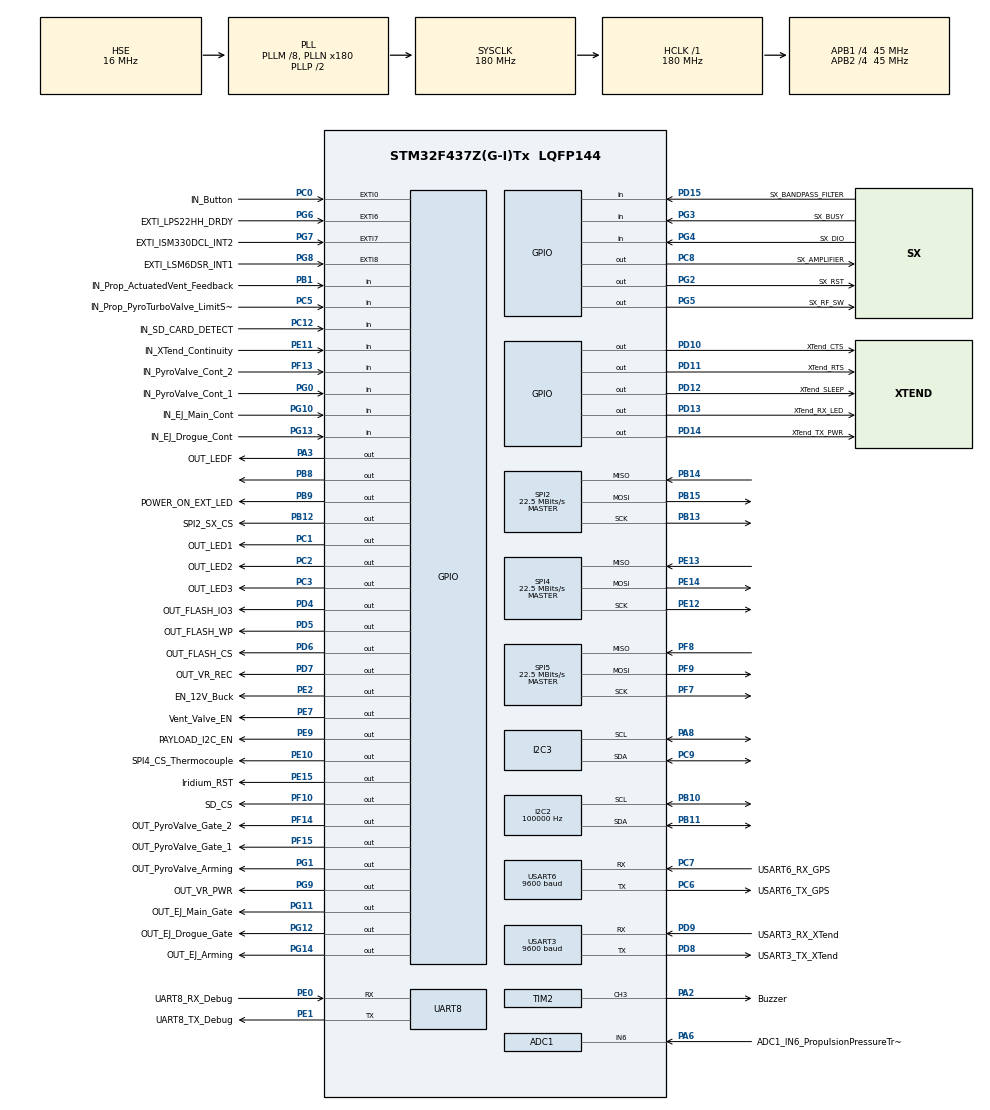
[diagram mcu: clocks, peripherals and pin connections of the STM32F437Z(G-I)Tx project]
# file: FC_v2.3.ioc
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ADC1.Channel-0\#ChannelRegularConversion=ADC_CHANNEL_6
ADC1.NbrOfConversionFlag=1
ADC1.Rank-0\#ChannelRegularConversion=1
ADC1.SamplingTime-0\#ChannelRegularConversion=ADC_SAMPLETIME_3CYCLES
ADC1.master=1
FREERTOS.INCLUDE_vTaskDelay=1
FREERTOS.Tasks01=Memory0,40,512,StartMemory0,Default,NULL,Dynamic,NULL,NULL;Ejection1,40,512,StartEjection1,Default,NULL,Dynamic,NULL,NULL;Telemetry2,48,1024,StartTelemetry2,Default,NULL,Dynamic,NULL,NULL;Sensors3,40,512,StartSensors3,Default,NULL,Dynamic,NULL,NULL;WatchDog,48,512,StartWatchDog,Default,NULL,Dynamic,NULL,NULL;Propulsion4,40,512,StartPropulsion4,Default,NULL,Dynamic,NULL,NULL
FREERTOS.configCHECK_FOR_STACK_OVERFLOW=0
FREERTOS.configMINIMAL_STACK_SIZE=512
FREERTOS.configTIMER_TASK_PRIORITY=55
FREERTOS.configTOTAL_HEAP_SIZE=24000
FREERTOS.configUSE_DAEMON_TASK_STARTUP_HOOK=1
FREERTOS.configUSE_NEWLIB_REENTRANT=1
I2C2.ClockSpeed=100000
I2C2.I2C_Mode=I2C_Standard
IWDG.Prescaler=IWDG_PRESCALER_64
IWDG.Reload=2499
Mcu.Family=STM32F4
Mcu.Name=STM32F437Z(G-I)Tx
Mcu.Package=LQFP144
NVIC.EXTI0_IRQn=true\:0\:0\:true\:false\:true\:false\:true\:true\:true
NVIC.PriorityGroup=NVIC_PRIORITYGROUP_4
NVIC.RTC_Alarm_IRQn=true\:0\:0\:true\:false\:false\:false\:true\:true\:true
NVIC.RTC_WKUP_IRQn=true\:0\:0\:true\:false\:true\:false\:true\:true\:true
NVIC.TIM6_DAC_IRQn=true\:15\:0\:true\:false\:true\:false\:false\:true\:true
NVIC.TimeBase=TIM6_DAC_IRQn
NVIC.TimeBaseIP=TIM6
PA13.Mode=Trace_Asynchronous_SW
PA13.Signal=SYS_JTMS-SWDIO
PA14.Mode=Trace_Asynchronous_SW
PA14.Signal=SYS_JTCK-SWCLK
PA2.GPIO_Label=Buzzer
PA2.Signal=S_TIM2_CH3
PA3.GPIO_Label=OUT_LEDF
PA3.Signal=GPIO_Output
PA6.GPIO_Label=ADC1_IN6_PropulsionPressureTransducer
PA6.Signal=ADCx_IN6
PA8.GPIO_Pu=GPIO_PULLUP
PA8.Mode=I2C
PA8.Signal=I2C3_SCL
PB1.GPIO_Label=IN_Prop_ActuatedVent_Feedback
PB1.Signal=GPIO_Input
PB10.GPIO_Pu=GPIO_PULLUP
PB10.Mode=I2C
PB10.Signal=I2C2_SCL
PB11.GPIO_Pu=GPIO_PULLUP
PB11.Mode=I2C
PB11.Signal=I2C2_SDA
PB12.GPIO_Label=SPI2_SX_CS
PB12.Signal=GPIO_Output
PB13.Mode=Full_Duplex_Master
PB13.Signal=SPI2_SCK
PB14.Mode=Full_Duplex_Master
PB14.Signal=SPI2_MISO
PB15.Mode=Full_Duplex_Master
PB15.Signal=SPI2_MOSI
PB3.Mode=Trace_Asynchronous_SW
PB3.Signal=SYS_JTDO-SWO
PB8.Signal=GPIO_Output
PB9.GPIO_Label=POWER_ON_EXT_LED
PB9.Signal=GPIO_Output
PC0.GPIO_Label=IN_Button
PC0.GPIO_ModeDefaultEXTI=GPIO_MODE_IT_FALLING
PC0.Signal=GPXTI0
PC1.GPIO_Label=OUT_LED1
PC1.Signal=GPIO_Output
PC12.GPIO_Label=IN_SD_CARD_DETECT
PC12.Signal=GPIO_Input
PC14/OSC32_IN.Mode=LSE-External-Oscillator
PC14/OSC32_IN.Signal=RCC_OSC32_IN
PC15/OSC32_OUT.Mode=LSE-External-Oscillator
PC15/OSC32_OUT.Signal=RCC_OSC32_OUT
PC2.GPIO_Label=OUT_LED2
PC2.Signal=GPIO_Output
PC3.GPIO_Label=OUT_LED3
PC3.Signal=GPIO_Output
PC5.GPIO_Label=IN_Prop_PyroTurboValve_LimitSwitch
PC5.Signal=GPIO_Input
PC6.GPIO_Label=USART6_TX_GPS
PC6.Mode=Asynchronous
PC6.Signal=USART6_TX
PC7.GPIO_Label=USART6_RX_GPS
PC7.Mode=Asynchronous
PC7.Signal=USART6_RX
PC8.GPIO_Label=SX_AMPLIFIER
PC8.Signal=GPIO_Output
PC9.GPIO_Pu=GPIO_PULLUP
PC9.Mode=I2C
PC9.Signal=I2C3_SDA
PD10.GPIO_Label=XTend_CTS
PD10.Signal=GPIO_Output
PD11.GPIO_Label=XTend_RTS
PD11.Signal=GPIO_Output
PD12.GPIO_Label=XTend_SLEEP
PD12.Signal=GPIO_Output
PD13.GPIO_Label=XTend_RX_LED
PD13.Signal=GPIO_Output
PD14.GPIO_Label=XTend_TX_PWR
PD14.Signal=GPIO_Output
PD15.GPIO_Label=SX_BANDPASS_FILTER
PD15.Signal=GPIO_Input
PD4.GPIO_Label=OUT_FLASH_IO3
PD4.GPIO_ModeDefaultOutputPP=GPIO_MODE_OUTPUT_PP
PD4.GPIO_PuPd=GPIO_PULLUP
PD4.PinState=GPIO_PIN_SET
PD4.Signal=GPIO_Output
PD5.GPIO_Label=OUT_FLASH_WP
PD5.GPIO_PuPd=GPIO_PULLUP
PD5.PinState=GPIO_PIN_SET
PD5.Signal=GPIO_Output
PD6.GPIO_Label=OUT_FLASH_CS
PD6.GPIO_PuPd=GPIO_PULLUP
PD6.PinState=GPIO_PIN_SET
PD6.Signal=GPIO_Output
PD7.GPIO_Label=OUT_VR_REC
PD7.Signal=GPIO_Output
PD8.GPIO_Label=USART3_TX_XTend
PD8.Mode=Asynchronous
PD8.Signal=USART3_TX
PD9.GPIO_Label=USART3_RX_XTend
PD9.Mode=Asynchronous
PD9.Signal=USART3_RX
PE0.GPIO_Label=UART8_RX_Debug
PE0.Mode=Asynchronous
PE0.Signal=UART8_RX
PE1.GPIO_Label=UART8_TX_Debug
PE1.Mode=Asynchronous
PE1.Signal=UART8_TX
PE10.GPIO_Label=SPI4_CS_Thermocouple
PE10.Signal=GPIO_Output
PE11.GPIO_Label=IN_XTend_Continuity
PE11.Signal=GPIO_Input
PE12.Mode=Full_Duplex_Master
PE12.Signal=SPI4_SCK
PE13.Mode=Full_Duplex_Master
PE13.Signal=SPI4_MISO
PE14.Mode=Full_Duplex_Master
PE14.Signal=SPI4_MOSI
PE15.GPIO_Label=Iridium_RST
PE15.Signal=GPIO_Output
PE2.GPIO_Label=EN_12V_Buck
PE2.Signal=GPIO_Output
PE7.GPIO_Label=Vent_Valve_EN
PE7.Signal=GPIO_Output
PE9.GPIO_Label=PAYLOAD_I2C_EN
PE9.Signal=GPIO_Output
PF10.GPIO_Label=SD_CS
PF10.GPIO_PuPd=GPIO_PULLUP
PF10.PinState=GPIO_PIN_SET
PF10.Signal=GPIO_Output
PF13.GPIO_Label=IN_PyroValve_Cont_2
PF13.Signal=GPIO_Input
PF14.GPIO_Label=OUT_PyroValve_Gate_2
PF14.Signal=GPIO_Output
PF15.GPIO_Label=OUT_PyroValve_Gate_1
PF15.Signal=GPIO_Output
PF7.GPIO_PuPd=GPIO_PULLUP
PF7.Mode=Full_Duplex_Master
PF7.Signal=SPI5_SCK
PF8.GPIO_PuPd=GPIO_PULLUP
PF8.Mode=Full_Duplex_Master
PF8.Signal=SPI5_MISO
PF9.GPIO_PuPd=GPIO_PULLUP
PF9.Mode=Full_Duplex_Master
PF9.Signal=SPI5_MOSI
PG0.GPIO_Label=IN_PyroValve_Cont_1
PG0.Signal=GPIO_Input
PG1.GPIO_Label=OUT_PyroValve_Arming
PG1.Signal=GPIO_Output
PG10.GPIO_Label=IN_EJ_Main_Cont
PG10.Signal=GPIO_Input
PG11.GPIO_Label=OUT_EJ_Main_Gate
PG11.Signal=GPIO_Output
PG12.GPIO_Label=OUT_EJ_Drogue_Gate
PG12.Signal=GPIO_Output
PG13.GPIO_Label=IN_EJ_Drogue_Cont
PG13.Signal=GPIO_Input
PG14.GPIO_Label=OUT_EJ_Arming
PG14.Signal=GPIO_Output
PG2.GPIO_Label=SX_RST
PG2.Signal=GPIO_Output
PG3.GPIO_Label=SX_BUSY
PG3.Signal=GPIO_Input
PG4.GPIO_Label=SX_DIO
PG4.Signal=GPIO_Input
PG5.GPIO_Label=SX_RF_SW
PG5.Signal=GPIO_Output
PG6.GPIO_Label=EXTI_LPS22HH_DRDY
PG6.Signal=GPXTI6
PG7.GPIO_Label=EXTI_ISM330DCL_INT2
PG7.Signal=GPXTI7
PG8.GPIO_Label=EXTI_LSM6DSR_INT1
PG8.Signal=GPXTI8
PG9.GPIO_Label=OUT_VR_PWR
PG9.Signal=GPIO_Output
PH0/OSC_IN.Mode=HSE-External-Oscillator
PH0/OSC_IN.Signal=RCC_OSC_IN
PH1/OSC_OUT.Mode=HSE-External-Oscillator
PH1/OSC_OUT.Signal=RCC_OSC_OUT
ProjectManager.HeapSize=0x600
ProjectManager.StackSize=0x400
ProjectManager.TargetToolchain=STM32CubeIDE
RCC.48MHZClocksFreq_Value=120000000
RCC.AHBFreq_Value=180000000
RCC.APB1CLKDivider=RCC_HCLK_DIV4
RCC.APB1Freq_Value=45000000
RCC.APB1TimFreq_Value=90000000
RCC.APB2CLKDivider=RCC_HCLK_DIV4
RCC.APB2Freq_Value=45000000
RCC.APB2TimFreq_Value=90000000
RCC.CortexFreq_Value=180000000
RCC.HCLKFreq_Value=180000000
RCC.HSE_VALUE=16000000
RCC.HSI_VALUE=16000000
RCC.PLLM=8
RCC.PLLN=180
RCC.PLLQ=3
RCC.PLLSourceVirtual=RCC_PLLSOURCE_HSE
RCC.SYSCLKFreq_VALUE=180000000
RCC.SYSCLKSource=RCC_SYSCLKSOURCE_PLLCLK
RCC.VCOOutputFreq_Value=360000000
RTC.Alarm=RTC_ALARM_A
RTC.Alarm_B=RTC_ALARM_B
RTC.Minutes_A=0
RTC.Minutes_B=0
RTC.Seconds_A=0
RTC.Seconds_B=0
SH.ADCx_IN6.0=ADC1_IN6,IN6
SH.S_TIM2_CH3.0=TIM2_CH3,PWM Generation3 CH3
SPI2.BaudRatePrescaler=SPI_BAUDRATEPRESCALER_2
SPI2.CalculateBaudRate=22.5 MBits/s
SPI2.Direction=SPI_DIRECTION_2LINES
SPI2.Mode=SPI_MODE_MASTER
SPI2.VirtualType=VM_MASTER
SPI4.BaudRatePrescaler=SPI_BAUDRATEPRESCALER_2
SPI4.CalculateBaudRate=22.5 MBits/s
SPI4.Direction=SPI_DIRECTION_2LINES
SPI4.Mode=SPI_MODE_MASTER
SPI4.VirtualType=VM_MASTER
SPI5.BaudRatePrescaler=SPI_BAUDRATEPRESCALER_2
SPI5.CalculateBaudRate=22.5 MBits/s
SPI5.Direction=SPI_DIRECTION_2LINES
SPI5.Mode=SPI_MODE_MASTER
SPI5.VirtualType=VM_MASTER
TIM2.Channel-PWM\ Generation3\ CH3=TIM_CHANNEL_3
TIM2.Period=400-1
TIM2.Prescaler=90-1
TIM2.Pulse-PWM\ Generation3\ CH3=100
TIM2.TIM_MasterOutputTrigger=TIM_TRGO_UPDATE
UART8.VirtualMode=Asynchronous
USART3.BaudRate=9600
USART3.VirtualMode=VM_ASYNC
USART6.BaudRate=9600
USART6.VirtualMode=VM_ASYNC
VP_FATFS_VS_Generic.Mode=User_defined
VP_FREERTOS_VS_CMSIS_V2.Mode=CMSIS_V2
VP_IWDG_VS_IWDG.Mode=IWDG_Activate
VP_RTC_VS_RTC_Activate.Mode=RTC_Enabled
VP_RTC_VS_RTC_Alarm_A_Intern.Mode=Alarm A
VP_RTC_VS_RTC_Alarm_B_Intern.Mode=Alarm B
VP_RTC_VS_RTC_Calendar.Mode=RTC_Calendar
VP_RTC_VS_RTC_WakeUp_intern.Mode=WakeUp
VP_SYS_VS_tim6.Mode=TIM6
VP_TIM2_VS_ClockSourceINT.Mode=Internal
board=custom

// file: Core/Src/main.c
/* USER CODE BEGIN Header */
/**
  ******************************************************************************
  * @file           : main.c
  * @brief          : Main program body
  ******************************************************************************
  * @attention
  *
  * <h2><center>&copy; Copyright (c) 2022 STMicroelectronics.
  * All rights reserved.</center></h2>
  *
  * This software component is licensed by ST under Ultimate Liberty license
  * SLA0044, the "License"; You may not use this file except in compliance with
  * the License. You may obtain a copy of the License at:
  *                             www.st.com/SLA0044
  *
  ******************************************************************************
  */
/* USER CODE END Header */
#include "main.h"
#include "cmsis_os.h"
#include "adc.h"
#include "fatfs.h"
#include "i2c.h"
#include "iwdg.h"
#include "rtc.h"
#include "spi.h"
#include "tim.h"
#include "usart.h"
#include "gpio.h"

/* USER CODE BEGIN Includes */

#include <MRT_setup.h>
#include <MRT_helpers.h>

/* USER CODE END Includes */

void SystemClock_Config(void);
void MX_FREERTOS_Init(void);
/* USER CODE BEGIN PFP */

void MRT_STM_Init(void);

/* USER CODE END PFP */

/* USER CODE BEGIN 0 */

int main(void){
	MRT_STM_Init();
	__HAL_DBGMCU_FREEZE_IWDG();	// pause IWDG and RTC during debugging
	__HAL_FREEZE_RTC_DBGMCU();
	println("\r\n\r\nSTM Init...OK");

	//The rest of the initialization is made in freertos.c by vApplicationDaemonTaskStartupHook()

	//TODO I2C SENSORS (lsm and lps) SOMETIMES DON'T WANT TO WORK ANYMORE -> NEED TO RESET THE POWER (Enter quick standByMode?)
	//check hardfault_handler

	//Initialize the os
	MX_FREERTOS_Init();

	//Starting the os
	println("\r\n/****Starting the OS****/\r\n");
	osKernelStart();

	println("SOMETHING WENT HORRIBLY WRONG, WAITING FOR WATCH DOG RESET");
	HAL_IWDG_Refresh(&hiwdg);
	MRT_Deinit();
	while (1){}
}

/* USER CODE END 0 */

void SystemClock_Config(void)
{
  RCC_OscInitTypeDef RCC_OscInitStruct = {0};
  RCC_ClkInitTypeDef RCC_ClkInitStruct = {0};

  /** Configure the main internal regulator output voltage
  */
  __HAL_RCC_PWR_CLK_ENABLE();
  __HAL_PWR_VOLTAGESCALING_CONFIG(PWR_REGULATOR_VOLTAGE_SCALE1);
  /** Initializes the RCC Oscillators according to the specified parameters
  * in the RCC_OscInitTypeDef structure.
  */
  RCC_OscInitStruct.OscillatorType = RCC_OSCILLATORTYPE_LSI|RCC_OSCILLATORTYPE_HSE;
  RCC_OscInitStruct.HSEState = RCC_HSE_ON;
  RCC_OscInitStruct.LSIState = RCC_LSI_ON;
  RCC_OscInitStruct.PLL.PLLState = RCC_PLL_ON;
  RCC_OscInitStruct.PLL.PLLSource = RCC_PLLSOURCE_HSE;
  RCC_OscInitStruct.PLL.PLLM = 8;
  RCC_OscInitStruct.PLL.PLLN = 180;
  RCC_OscInitStruct.PLL.PLLP = RCC_PLLP_DIV2;
  RCC_OscInitStruct.PLL.PLLQ = 3;
  if (HAL_RCC_OscConfig(&RCC_OscInitStruct) != HAL_OK)
  {
    Error_Handler();
  }
  /** Activate the Over-Drive mode
  */
  if (HAL_PWREx_EnableOverDrive() != HAL_OK)
  {
    Error_Handler();
  }
  /** Initializes the CPU, AHB and APB buses clocks
  */
  RCC_ClkInitStruct.ClockType = RCC_CLOCKTYPE_HCLK|RCC_CLOCKTYPE_SYSCLK
                              |RCC_CLOCKTYPE_PCLK1|RCC_CLOCKTYPE_PCLK2;
  RCC_ClkInitStruct.SYSCLKSource = RCC_SYSCLKSOURCE_PLLCLK;
  RCC_ClkInitStruct.AHBCLKDivider = RCC_SYSCLK_DIV1;
  RCC_ClkInitStruct.APB1CLKDivider = RCC_HCLK_DIV4;
  RCC_ClkInitStruct.APB2CLKDivider = RCC_HCLK_DIV4;

  if (HAL_RCC_ClockConfig(&RCC_ClkInitStruct, FLASH_LATENCY_5) != HAL_OK)
  {
    Error_Handler();
  }
}

/* USER CODE BEGIN 4 */

void MRT_STM_Init(void){
	HAL_Init();
	SystemClock_Config();

	MX_GPIO_Init();
	MX_ADC1_Init();
	MX_I2C2_Init();
	MX_I2C3_Init();
	MX_SPI2_Init();
	MX_SPI4_Init();
	MX_SPI5_Init();
	MX_TIM2_Init();
	MX_UART8_Init();
	MX_USART3_UART_Init();
	MX_USART6_UART_Init();
	MX_RTC_Init();
	//MX_IWDG_Init(); TODO ADDED IN MRT_Init()
	MX_FATFS_Init();
}

/* USER CODE END 4 */

void HAL_TIM_PeriodElapsedCallback(TIM_HandleTypeDef *htim)
{
  if (htim->Instance == TIM6) {
    HAL_IncTick();
  }
}

void Error_Handler(void)
{
  __disable_irq();
  while (1)
  {
  }
}

/************************ (C) COPYRIGHT STMicroelectronics *****END OF FILE****/

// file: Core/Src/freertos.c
/* USER CODE BEGIN Header */
/**
  ******************************************************************************
  * File Name          : freertos.c
  * Description        : Code for freertos applications
  ******************************************************************************
  * @attention
  *
  * <h2><center>&copy; Copyright (c) 2022 STMicroelectronics.
  * All rights reserved.</center></h2>
  *
  * This software component is licensed by ST under Ultimate Liberty license
  * SLA0044, the "License"; You may not use this file except in compliance with
  * the License. You may obtain a copy of the License at:
  *                             www.st.com/SLA0044
  *
  ******************************************************************************
  */
/* USER CODE END Header */

#include "FreeRTOS.h"
#include "task.h"
#include "main.h"
#include "cmsis_os.h"

/* USER CODE BEGIN Includes */
#include <iwdg.h>
#include <rtc.h>
#include "stm32f4xx_it.h" //Flag A and B for alarms A and B and reset from start function

#include <MRT_setup.h>
#include <MRT_helpers.h>
#include <MRT_ejection.h>
#include <MRT_propulsion.h>
#include <MRT_telemetry.h>
#include <MRT_memory.h>
#include <MRT_i2c_sensors.h>
#include <MRT_iridium.h>
#include <MRT_payload.h>
#include <video_recorder.h>

#include <sx126x.h> //sx126x_cfg_rx_boosted(&SRADIO_SPI,bool);

/* USER CODE END Includes */

/* USER CODE BEGIN Variables */

float altitude_m = 0; //Altitude of the rocket in meters
uint8_t wd_ejection_flag = 0; //Flag for the watch dog. When set to 1, the watch dog thread save the ejection stage in the external flash
osThreadId_t threadsID[NUMBER_OF_THREADS]; //Thread list accessed by Watch Dog thread

/* USER CODE END Variables */
/* Definitions for Memory0 */
osThreadId_t Memory0Handle;
const osThreadAttr_t Memory0_attributes = {
  .name = "Memory0",
  .stack_size = 512 * 4,
  .priority = (osPriority_t) osPriorityHigh,
};
/* Definitions for Ejection1 */
osThreadId_t Ejection1Handle;
const osThreadAttr_t Ejection1_attributes = {
  .name = "Ejection1",
  .stack_size = 512 * 4,
  .priority = (osPriority_t) osPriorityHigh,
};
/* Definitions for Telemetry2 */
osThreadId_t Telemetry2Handle;
const osThreadAttr_t Telemetry2_attributes = {
  .name = "Telemetry2",
  .stack_size = 1024 * 4,
  .priority = (osPriority_t) osPriorityRealtime,
};
/* Definitions for Sensors3 */
osThreadId_t Sensors3Handle;
const osThreadAttr_t Sensors3_attributes = {
  .name = "Sensors3",
  .stack_size = 512 * 4,
  .priority = (osPriority_t) osPriorityHigh,
};
/* Definitions for WatchDog */
osThreadId_t WatchDogHandle;
const osThreadAttr_t WatchDog_attributes = {
  .name = "WatchDog",
  .stack_size = 512 * 4,
  .priority = (osPriority_t) osPriorityRealtime,
};
/* Definitions for Propulsion4 */
osThreadId_t Propulsion4Handle;
const osThreadAttr_t Propulsion4_attributes = {
  .name = "Propulsion4",
  .stack_size = 512 * 4,
  .priority = (osPriority_t) osPriorityHigh,
};

/* USER CODE BEGIN FunctionPrototypes */

void MRT_waitForLaunch(void);
void MRT_checkThreadStates(void);

/* USER CODE END FunctionPrototypes */

void StartMemory0(void *argument);
void StartEjection1(void *argument);
void StartTelemetry2(void *argument);
void StartSensors3(void *argument);
void StartWatchDog(void *argument);
void StartPropulsion4(void *argument);

void MX_FREERTOS_Init(void); /* (MISRA C 2004 rule 8.1) */

/* Hook prototypes */
void vApplicationDaemonTaskStartupHook(void);

/* USER CODE BEGIN DAEMON_TASK_STARTUP_HOOK */
void vApplicationDaemonTaskStartupHook(void)
{
	buzz_fc_on();

	MRT_Init();

	println("\r\n\r\n/****Starting FC****/\r\n\r\n");
	HAL_IWDG_Refresh(&hiwdg);
	buzz_startup_success();

	MRT_waitForLaunch();

	print("\tCreating the threads...");

	/* Create the thread(s) */
	/* creation of Sensors3 */
	Sensors3Handle = osThreadNew(StartSensors3, NULL, &Sensors3_attributes);

	/* creation of Memory0 */
	Memory0Handle = osThreadNew(StartMemory0, NULL, &Memory0_attributes);

	/* creation of Ejection1 */
	Ejection1Handle = osThreadNew(StartEjection1, NULL, &Ejection1_attributes);

	/* creation of Telemetry2 */
	Telemetry2Handle = osThreadNew(StartTelemetry2, NULL, &Telemetry2_attributes);

	/* creation of Propulsion4 */
	Propulsion4Handle = osThreadNew(StartPropulsion4, NULL, &Propulsion4_attributes);

	/* creation of WatchDog */
	WatchDogHandle = osThreadNew(StartWatchDog, NULL, &WatchDog_attributes);

	println("OK");
}
/* USER CODE END DAEMON_TASK_STARTUP_HOOK */

void MX_FREERTOS_Init(void) {
  /* USER CODE BEGIN Init */

	println("\r\nFREERTOS Init");
	print("\tInitializing the kernel...");
	osKernelInitialize();
	println("OK");

  /* USER CODE END Init */

  /* USER CODE BEGIN RTOS_QUEUES */
  /* add queues, ... */
	//TODO No thread creation here (check vApplicationDaemonTaskStartupHook)
#if NO_THREAD_CREATION_HERE
  /* USER CODE END RTOS_QUEUES */

  /* Create the thread(s) */
  /* creation of Memory0 */
  Memory0Handle = osThreadNew(StartMemory0, NULL, &Memory0_attributes);

  /* creation of Ejection1 */
  Ejection1Handle = osThreadNew(StartEjection1, NULL, &Ejection1_attributes);

  /* creation of Telemetry2 */
  Telemetry2Handle = osThreadNew(StartTelemetry2, NULL, &Telemetry2_attributes);

  /* creation of Sensors3 */
  Sensors3Handle = osThreadNew(StartSensors3, NULL, &Sensors3_attributes);

  /* creation of WatchDog */
  WatchDogHandle = osThreadNew(StartWatchDog, NULL, &WatchDog_attributes);

  /* creation of Propulsion4 */
  Propulsion4Handle = osThreadNew(StartPropulsion4, NULL, &Propulsion4_attributes);

  /* USER CODE BEGIN RTOS_THREADS */
  /* add threads, ... */
#endif
  /* USER CODE END RTOS_THREADS */

}

void StartMemory0(void *argument)
{
  /* USER CODE BEGIN StartMemory0 */

	//Add thread id to the list
	threadsID[0]=osThreadGetId();

	#if !MEMORY_THREAD
    osThreadExit();
	#endif

    fres = sd_open_file(filename);

    //uint8_t reset_counter = 0;
    uint8_t sync_counter = 0;

  /* Infinite loop */
  for(;;)
  {
	 //Get RTC time
	 HAL_RTC_GetTime(&hrtc, &sTime, RTC_FORMAT_BIN);
	 HAL_RTC_GetDate(&hrtc, &sDate, RTC_FORMAT_BIN);

	 //Update global variables
	 prev_hour = sTime.Hours;
	 prev_min = sTime.Minutes;
	 prev_sec = sTime.Seconds;
	 if (__HAL_RTC_SHIFT_GET_FLAG(&hrtc, RTC_FLAG_SHPF)) prev_sec++; //Adjust following the user manual
	 prev_subsec = sTime.SubSeconds;

	// Save to SD card
	#if SD_CARD_
	sync_counter++;
	MRT_formatAvionics();

	if (sd_write(&fil,(uint8_t*) msg_buffer_av)<0){
		println("SD card error, closing and opening");
		f_close(&fil);
		osDelay(100);
		fres = sd_open_file(filename);
	}

	if (ejection_stage_flag < MAIN_DESCENT){
		MRT_formatPropulsion();
		if (sd_write(&fil,(uint8_t*) msg_buffer_pr)<0){
			println("SD card error, closing and opening");
			f_close(&fil);
			osDelay(100);
			fres = sd_open_file(filename);
		}
	}

	if (sync_counter == 50) {
		sync_counter=0;
		f_sync(&fil);
	}
	#endif

	if (ejection_stage_flag >= LANDED){
	  osDelay(1000/POST_LANDED_DATA_FREQ);
	}
	else{
		osDelay(1000/DATA_FREQ);
	}
  }

  //In case it leaves the infinite loop
  println((char*) "Something went wrong with thread 0");
  osThreadExit();

  /* USER CODE END StartMemory0 */
}

void StartEjection1(void *argument)
{
  /* USER CODE BEGIN StartEjection1 */

	//Add thread id to the list
	threadsID[1]=osThreadGetId();

	#if !EJECTION_THREAD
	osThreadExit();
	#endif

	//Double check the state TODO bad? (say wakeup flag is raised but ground isn't reached yet
	if (ejection_stage_flag >= LANDED)  osThreadExit(); //Ground reached

	uint8_t lsl_counter = 0;
	uint8_t acc_counter = 0;

  /* Infinite loop */
  for(;;)
  {
	  //Check acceleration
	  if (MRT_getAccNorm() < ACC_LIMIT){
		  acc_counter++;
	  }

	  //Update true apogee
	  if (altitude_m > rtc_bckp_reg_alt_true_apogee){
		  rtc_bckp_reg_alt_true_apogee = altitude_m;
		  rtc_bckp_reg_true_apogee_time = 100*prev_min + prev_sec;
	  }
	  else{
		  #if TESTING_EJECTION
		  acc_counter = ACC_COUNTER_THRESH + 1;
		  #endif

		  //Check if we are going down and if almost no acceleration (close to apogee)
		  if(LSLinRegression() < LSL_SLOPE_LIMIT && acc_counter > ACC_COUNTER_THRESH){
			  lsl_counter++;
		  }
		  else{
			  //lsl_counter = 0;
		  }

		  if (lsl_counter >= LSL_COUNTER_THRESHOLD || ejection_stage_flag >= DROGUE_DESCENT){

			  if (ejection_stage_flag < DROGUE_DESCENT){

				  //TODO update value to be saved in rtc bckp registers
				  rtc_bckp_reg_alt_apogee = altitude_m;
				  rtc_bckp_reg_apogee_time = 100*prev_min + prev_sec;

				  //Update state (save the state in WatchDog thread)
				  ejection_stage_flag = DROGUE_DESCENT;
				  apogee_flag = 1; //Apogee reached //TODO is it where we change it???
				  wd_ejection_flag = 1; //Raise the flag

				  println("Eject Drogue");
			  }

			  //Put outside of "if" such that we only need to remember the ejection stage instead if it + arming state
			  //TODO should I put a while loop, a foor loop or just "one time functions"?
			  while(!HAL_GPIO_ReadPin(OUT_EJ_Arming_GPIO_Port, OUT_EJ_Arming_Pin)){
				  HAL_GPIO_WritePin(OUT_EJ_Arming_GPIO_Port, OUT_EJ_Arming_Pin, SET); //PG14 ARMING RCOV
			  }
			  while(!HAL_GPIO_ReadPin(OUT_EJ_Drogue_Gate_GPIO_Port, OUT_EJ_Drogue_Gate_Pin)){
				  HAL_GPIO_WritePin(OUT_EJ_Drogue_Gate_GPIO_Port, OUT_EJ_Drogue_Gate_Pin, SET); //PG12 DROGUE GATE
			  }
			  while(HAL_GPIO_ReadPin(OUT_EJ_Arming_GPIO_Port, OUT_EJ_Arming_Pin)){
				  HAL_GPIO_WritePin(OUT_EJ_Arming_GPIO_Port, OUT_EJ_Arming_Pin, RESET); //PG14 ARMING RCOV
			  }

			  //Minimum delay between drogue and main
			  osDelay(DROGUE_TO_MAIN_DELAY);

			  for(;;){

				  //We reached main deployment altitude
				  if (altitude_m < MAIN_DEPLOY_ALT || ejection_stage_flag >= MAIN_DESCENT){

					  if (ejection_stage_flag < MAIN_DESCENT){

						  //TODO update value to be saved in rtc bckp registers
						  rtc_bckp_reg_alt_main = altitude_m;
						  rtc_bckp_reg_main_time = 100*prev_min + prev_sec;

						  //Update state (save the state in WatchDog thread)
						  ejection_stage_flag = MAIN_DESCENT;
						  wd_ejection_flag = 1; //Raise the flag

						  println("Eject Main");
					  }

					  //Put outside of "if" such that we only need to remember the ejection stage instead if it + arming state
					  //TODO should I put a while loop, a foor loop or just "one time functions"?
					  while(!HAL_GPIO_ReadPin(OUT_EJ_Arming_GPIO_Port, OUT_EJ_Arming_Pin)){
						  HAL_GPIO_WritePin(OUT_EJ_Arming_GPIO_Port, OUT_EJ_Arming_Pin, SET); //PG14 ARMING RCOV
					  }
					  while(!HAL_GPIO_ReadPin(OUT_EJ_Main_Gate_GPIO_Port, OUT_EJ_Main_Gate_Pin)){
						  HAL_GPIO_WritePin(OUT_EJ_Main_Gate_GPIO_Port, OUT_EJ_Main_Gate_Pin, SET); //PG11 MAIN GATE
					  }
					  while(HAL_GPIO_ReadPin(OUT_EJ_Arming_GPIO_Port, OUT_EJ_Arming_Pin)){
						  HAL_GPIO_WritePin(OUT_EJ_Arming_GPIO_Port, OUT_EJ_Arming_Pin, RESET); //PG14 ARMING RCOV
					  }

					  uint8_t prev_altitude = 0;
					  uint8_t cur_altitude = 0;
					  uint8_t counter = 0;
					  while(counter < 5){

						  cur_altitude = altitude_m;

						  if (MAX(cur_altitude - prev_altitude, cur_altitude - prev_altitude) < LANDING_DIFF_LIMIT){
							  counter++;
						  }
						  else{
							  counter = 0;
						  }
						  prev_altitude = cur_altitude;
						  osDelay(1000/EJECTION_FREQ);
					  }

					  //TODO update value to be saved in rtc bckp registers
					  rtc_bckp_reg_alt_landed = altitude_m;
					  rtc_bckp_reg_landed_time = 100*prev_min + prev_sec;

					  //Update state (saved state in WatchDog thread)
					  ejection_stage_flag = LANDED;
					  wd_ejection_flag = 1;

					  VR_Stop_Rec();
					  VR_Power_Off();

					  println("Ground Level Reached");
					  osThreadExit();

				  }
				  osDelay(1000/EJECTION_FREQ);
			  }
		  }
	  }
	  osDelay(1000/EJECTION_FREQ);
  }

  //In case it leaves the infinite loop
  println((char*) "Something went wrong with thread 1");
  osThreadExit();

  /* USER CODE END StartEjection1 */
}

void StartTelemetry2(void *argument)
{
  /* USER CODE BEGIN StartTelemetry2 */

	//Add thread id to the list
	threadsID[2]=osThreadGetId();

	#if !TELEMETRY_THREAD
	osThreadExit();
	#endif

	char radio_buffer[RADIO_BUFFER_SIZE];
	uint8_t counter = 0;

  /* Infinite loop */
  for(;;)
  {
	  HAL_GPIO_WritePin(OUT_LED3_GPIO_Port, OUT_LED3_Pin, SET);

	  if (ejection_stage_flag >= LANDED){
		  osDelay(1000/POST_LANDED_SEND_FREQ);
	  }
	  else if (apogee_flag){
		  osDelay(1000/POST_APOGEE_SEND_FREQ);
	  }
	  else{ //Only send prop data pre-apogee

		  //Send propulsion data
		  memset(radio_buffer, 0, RADIO_BUFFER_SIZE);
		  MRT_formatPropulsion();
		  memcpy(radio_buffer, msg_buffer_pr, strlen(msg_buffer_pr));
		  MRT_radio_tx((char*) radio_buffer);

		  osDelay(1000/PRE_APOGEE_SEND_FREQ);
	  }

	  if (counter == SENSORS_SEND_FREQ_DIVIDER){
		  counter = 0;

		  //TODO Need to make this 't' variable from the Iridium or convert the seconds from the GPS
		  /*
		  HOUR = t.tm_hour;
		  MIN = t.tm_min;
		  SEC = t.tm_sec;
		  */

		  //From the GPS time value
		  /*
		  float MIN = ((uint8_t) time % 3600) / 60.0; sprintf(&MIN, "%.0f",MIN);
		  float SEC = (uint8_t) time % 60; sprintf(&SEC,"%.0f",SEC);
		  float SUBSEC = time / 3600.0; sprintf(&SUBSEC,"%.0f",SUBSEC);
		  */

	  	  //Send sensors data
		  memset(radio_buffer, 0, RADIO_BUFFER_SIZE);
		  MRT_formatAvionics();
		  memcpy(radio_buffer, msg_buffer_av, strlen(msg_buffer_av));
		  MRT_radio_tx((char*) radio_buffer);
	  }
	  counter++;

	  HAL_GPIO_WritePin(OUT_LED3_GPIO_Port, OUT_LED3_Pin, RESET);
  }

  //In case it leaves the infinite loop
  println((char*) "Something went wrong with thread 2");
  osThreadExit();

  /* USER CODE END StartTelemetry2 */
}

void StartSensors3(void *argument)
{
  /* USER CODE BEGIN StartSensors3 */

	//Add thread id to the list
	threadsID[3]=osThreadGetId();

	#if !SENSORS_THREAD
	osThreadExit();
	#endif

  /* Infinite loop */
  for(;;)
  {
	  HAL_GPIO_WritePin(OUT_LED1_GPIO_Port, OUT_LED1_Pin, SET);

	  //GPS
	  hgps.pollAll();

	  //LSM6DSR
	  hlsm6dsr.pollAll();

	  //LPS22HH
	  hlps22hh.pollAll();

	  //Update altitude
	  //altitude_m = MRT_getAltitude(hlps22hh.pressure_hPa); //TODO changed
	  //altitude_m = runAltitudeMeasurements(HAL_GetTick(), MRT_getAltitude(hlps22hh.pressure_hPa));
	  altitude_m = runAltitudeMeasurements(xTaskGetTickCount(), MRT_getAltitude(hlps22hh.pressure_hPa)); //TODO RTOS equivalent?

	  //Gates continuity
	  gates_continuity = MRT_getContinuity();

	  HAL_GPIO_WritePin(OUT_LED1_GPIO_Port, OUT_LED1_Pin, RESET);

	  if (ejection_stage_flag >= LANDED){
		  osDelay(1000/POST_LANDED_POLL_FREQ);
	  }
	  else if (apogee_flag){
		  osDelay(1000/POST_APOGEE_POLL_FREQ);
	  }
	  else{
		  osDelay(1000/PRE_APOGEE_POLL_FREQ);
	  }
  }

  //In case it leaves the infinite loop
  println((char*) "Something went wrong with thread 3");
  osThreadExit();

  /* USER CODE END StartSensors3 */
}

void StartWatchDog(void *argument)
{
  /* USER CODE BEGIN StartWatchDog */

	#if !WATCHDOG_THREAD
	osThreadExit();
	#endif

	char buffer[WD_BUFFER_SIZE];

  /* Infinite loop */
  for(;;)
  {
	 HAL_GPIO_WritePin(OUT_LED2_GPIO_Port, OUT_LED2_Pin, SET);

	 HAL_IWDG_Refresh(&hiwdg);

	#if HARDFAULT_GENERATOR
	 uint64_t* i = 0x20CDCDCD;
	 *i = 10;
	#endif

	 //Check if new ejection stage to save in memory
	 if(wd_ejection_flag == 1){

		wd_ejection_flag = 0;

		//Update ejection stage flag and save it
		rtc_bckp_reg_ejection_stage = ejection_stage_flag;
		ext_flash_ejection_stage = ejection_stage_flag;
		MRT_saveFlagValue(FC_STATE_FLIGHT);

		//If applicable, update apogee flag
		if (ejection_stage_flag >= DROGUE_DESCENT){
			apogee_flag = 1;
			rtc_bckp_reg_apogee = apogee_flag;
			ext_flash_apogee = apogee_flag;
			MRT_saveFlagValue(FC_STATE_APOGEE);
		}

		//TODO TESTING SAVE EVERY ALTITUDE REGISTERS
		MRT_RTC_setBackupReg(FC_STATE_ALT_PAD, rtc_bckp_reg_alt_pad);
		MRT_RTC_setBackupReg(FC_PAD_TIME, rtc_bckp_reg_pad_time);
		MRT_RTC_setBackupReg(FC_STATE_TRUE_APOGEE, rtc_bckp_reg_alt_true_apogee);
		MRT_RTC_setBackupReg(FC_TRUE_APOGEE_TIME, rtc_bckp_reg_true_apogee_time);
		MRT_RTC_setBackupReg(FC_STATE_ALT_APOGEE, rtc_bckp_reg_alt_apogee);
		MRT_RTC_setBackupReg(FC_APOGEE_TIME, rtc_bckp_reg_apogee_time);
		MRT_RTC_setBackupReg(FC_STATE_ALT_MAIN, rtc_bckp_reg_alt_main);
		MRT_RTC_setBackupReg(FC_MAIN_TIME, rtc_bckp_reg_main_time);
		MRT_RTC_setBackupReg(FC_STATE_ALT_LANDED, rtc_bckp_reg_alt_landed);
		MRT_RTC_setBackupReg(FC_LANDED_TIME, rtc_bckp_reg_landed_time);
	 }

	  #if !NO_SLEEP
	  //Check if it's sleep time
	  if (flagA==1 || flagB==1){
		//Update iwdg_flag
		iwdg_flag = 1;
		rtc_bckp_reg_iwdg = iwdg_flag;
		ext_flash_iwdg = iwdg_flag;
		MRT_saveFlagValue(FC_STATE_IWDG);

		//Save the RTC time
		MRT_saveTotalTime();

		//Reset to deactivate IWDG
		NVIC_SystemReset();
	  }
	  #endif

	  //Save the RTC time
	  MRT_saveTotalTime();

	  //Check for complete restart
	  if(restart_flag == 1){
		  #if !FLIGHT_MODE
		  MRT_resetFromStart();
		  #endif
	  }

	  MRT_checkThreadStates();

	  HAL_IWDG_Refresh(&hiwdg);

	  HAL_GPIO_WritePin(OUT_LED2_GPIO_Port, OUT_LED2_Pin, RESET);

	  osDelay(1000/WD_FREQ);
  }

  //In case it leaves the infinite loop
  println((char*) "Something went wrong with thread WD");
  osThreadExit();

  /* USER CODE END StartWatchDog */
}

void StartPropulsion4(void *argument)
{
  /* USER CODE BEGIN StartPropulsion4 */

	//Add thread id to the list
	threadsID[4]=osThreadGetId();

	#if !PROPULSION_THREAD
	osThreadExit();
	#endif

	#if !IRIDIUM_
	if (apogee_flag || ejection_stage_flag >= DROGUE_DESCENT){
		osThreadExit();
	}
	#endif

	#if TESTING_IRIDIUM
	apogee_flag = 1;
	#endif

	payload_buffer[0] = 'P';
	iridium_buffer[0] = 'S';
	iridium_buffer[9] = 'E';
	uint8_t timeout_changed = 0;
	uint16_t payload_counter = 0; //Was sending too fast relative to thread

  /* Infinite loop */
  for(;;)
  {
	  /* TODO scratch payload integration
	  //if between boost and landing send payload data over iridium
	  if (payload_counter>=PAYLOAD_COUNT*4 && ejection_stage_flag < LANDED){
		  payload_counter = 0;
		  if(payload_init_success){
			#if IRIDIUM_ //Iridium send
			if(MRT_payloadPoll() == 1){
				  HAL_GPIO_WritePin(OUT_LEDF_GPIO_Port, OUT_LEDF_Pin, SET);
				  osDelay(50);
				  print("\tPayload sending: ");
				  println(payload_buffer);
				  if(hiridium.getNetworkAvailability()){
					  osDelay(100);
					  hiridium.sendMessage(payload_buffer);
				  }
				  memset(payload_buffer+1,0,PAYLOAD_BUFFER_SIZE-1); //Everything but the beginning and ending characters
				  HAL_GPIO_WritePin(OUT_LEDF_GPIO_Port, OUT_LEDF_Pin, RESET);
			}
			#endif
		  }
		  else{
			  MRT_payloadInit();
		  }

	  }
	  */
	  if (apogee_flag || prev_hour >= 4){

			#if IRIDIUM_ //Iridium send

		    payload_counter = PAYLOAD_COUNT*4;

		  	//Adjust timeout when landing
			if (!timeout_changed && ejection_stage_flag == LANDED) {
			  //Set for the rest of the flight
			  timeout_changed = 1;
			  hiridium.adjustTimeout(IRIDIUM_LANDED_TIMEOUT); //Adjust timeout when landed
			}

			if(MRT_formatIridium() == 1){
			  HAL_GPIO_WritePin(OUT_LEDF_GPIO_Port, OUT_LEDF_Pin, SET);
			  osDelay(50);
			  //TODO make a list of latest coordinates retrieved to optimize the credits we use
			  print("\tIridium sending: ");
			  println(iridium_buffer);
			  if(hiridium.getNetworkAvailability()){
				  osDelay(100);
				  hiridium.sendMessage(iridium_buffer);
			  }
			  memset(iridium_buffer+1,0,IRIDIUM_BUFFER_SIZE-2); //Everything but the beginning and ending characters
			  HAL_GPIO_WritePin(OUT_LEDF_GPIO_Port, OUT_LEDF_Pin, RESET);
			}

			if (ejection_stage_flag >= LANDED){
			  osDelay(1000/POST_LANDED_SEND_FREQ);
			}
			else{
			  osDelay(IRIDIUM_WAIT_TIME);
			}
			//osDelay(1000/POST_APOGEE_POLL_FREQ);
			#else
			osThreadExit();
			#endif

	  }
	  else{
		  //Poll propulsion sensors
		  MRT_pollPropulsion();
		  payload_counter++;
		  osDelay(1000/PRE_APOGEE_POLL_FREQ);
	  }
  }

  //In case it leaves the infinite loop
  println((char*) "Something went wrong with thread 4");
  osThreadExit();

  /* USER CODE END StartPropulsion4 */
}

/* USER CODE BEGIN Application */

void MRT_waitForLaunch(void){

	println("Waiting for launch command from ground station\r\n");

	char radio_buffer[RADIO_BUFFER_SIZE];
	radio_command cmd = -1;

	//Increase radio gain (more power used)
	//sx126x_cfg_rx_boosted(&SRADIO_SPI,true);

	//Reduce power used by radios (reduce gain)
	//sx126x_cfg_rx_boosted(&SRADIO_SPI,false);

	//Open SD card file
	fres = sd_open_file(filename);
	uint8_t sync_counter = 0;

	#if TESTING_IRIDIUM
	ejection_stage_flag = BOOST;
	#endif

	//Poll propulsion until launch command sent
	while((XTEND_ || SRADIO_) && ejection_stage_flag == PAD){
		HAL_GPIO_WritePin(OUT_LED3_GPIO_Port, OUT_LED3_Pin, SET);

		HAL_IWDG_Refresh(&hiwdg);

		//Start measuring altitude
		hlps22hh.getPressure();
	    //altitude_m = MRT_getAltitude(hlps22hh.pressure_hPa); //TODO changed
	    //altitude_m = runAltitudeMeasurements(HAL_GetTick(), MRT_getAltitude(hlps22hh.pressure_hPa));
	    altitude_m = runAltitudeMeasurements(xTaskGetTickCount(), MRT_getAltitude(hlps22hh.pressure_hPa)); //TODO RTOS equivalent?

		//Get RTC time
		HAL_RTC_GetTime(&hrtc, &sTime, RTC_FORMAT_BIN);
		HAL_RTC_GetDate(&hrtc, &sDate, RTC_FORMAT_BIN);

		//Update global variables
		prev_hour = sTime.Hours;
		prev_min = sTime.Minutes;
		prev_sec = sTime.Seconds;
		if (__HAL_RTC_SHIFT_GET_FLAG(&hrtc, RTC_FLAG_SHPF)) prev_sec++; //Adjust following the user manual
		prev_subsec = sTime.SubSeconds;

		//Save the RTC time
	    MRT_saveTotalTime();

		//Poll propulsion sensors
		MRT_pollPropulsion();

		//Send propulsion data
		MRT_formatPropulsion();
		MRT_radio_tx(msg_buffer_pr);

		// Save to SD card
		#if SD_CARD_
		sync_counter++;
		if (sd_write(&fil,(uint8_t*) msg_buffer_pr) < 0){
			f_close(&fil);
			fres = sd_open_file(filename);
		}
		if (sync_counter==10){
			sync_counter=0;
			f_sync(&fil);
		}
		#endif

		//Check for complete restart
		if(restart_flag == 1){
		  #if !FLIGHT_MODE
		  MRT_resetFromStart();
		  #endif
		}

		//Refresh before using radio
		HAL_IWDG_Refresh(&hiwdg);

		#if HALF_BYTE_
		//Check for command (encoded so 1 byte received instead of 2)
		memset(radio_buffer, 0, RADIO_BUFFER_SIZE);
		MRT_radio_rx(radio_buffer, 1, 0x500); //Timeout is about 1.2 sec (should be less than 5 sec)
		#else
		memset(radio_buffer, 0, RADIO_BUFFER_SIZE);
		MRT_radio_rx(radio_buffer, 2, 0x25); //Timeout is about 0.6 sec (should be less than 5 sec)
		#endif
		cmd = radio_parse_command(radio_buffer);

		if (cmd == LAUNCH){
			//Update ejection stage flag and save it
			ejection_stage_flag = BOOST;
			rtc_bckp_reg_ejection_stage = BOOST;
			ext_flash_ejection_stage = BOOST;
			MRT_saveFlagValue(FC_STATE_FLIGHT);

			//Todo to test ejection
			rtc_bckp_reg_alt_pad = altitude_m;
			MRT_RTC_setBackupReg(FC_STATE_ALT_PAD, rtc_bckp_reg_alt_pad);
			rtc_bckp_reg_pad_time = 100*prev_min + prev_sec;
			MRT_RTC_setBackupReg(FC_PAD_TIME, rtc_bckp_reg_pad_time);
		}

		if (cmd>=1 && cmd<=11){
			execute_parsed_command(cmd);
			for(int i=0;i<3;i++){
				MRT_radio_send_ack(cmd);
			}
		}

		HAL_GPIO_WritePin(OUT_LED3_GPIO_Port, OUT_LED3_Pin, RESET);

		//Reset IWDG timer
		HAL_IWDG_Refresh(&hiwdg);

		osDelay(1000/PRE_APOGEE_SEND_FREQ);
	}

	//Close SD card (reopened by FreeRTOS)
	f_close(&fil);

	//Reduce power used by radios (reduce gain)
	//sx126x_cfg_rx_boosted(&SRADIO_SPI,false);
}

void MRT_checkThreadStates(void){
	  //Check each thread state
	  #if THREAD_KEEPER

	  osThreadState_t thread_state;

	  for (int i=0; i < NUMBER_OF_THREADS;i++){

		  thread_state = osThreadGetState(threadsID[i]);

		  if (thread_state == osThreadInactive ||
			  thread_state == osThreadBlocked){

			  //Ejection thread
			  if (i==1 && ejection_stage_flag < LANDED){
				 osThreadResume(threadsID[i]);
			  }

			  //Propulsion thread
			  #if !IRIDIUM_
			  if (i==4 && (apogee_flag || ejection_stage_flag >= DROGUE_DESCENT)){
				  osThreadTerminate(threadsID[i]);
			  }
			  #endif
			  else {
				 //Resume otherwise
				 osThreadResume(threadsID[i]);
			  }
		  }
		  else if (thread_state == osThreadError){
			  //If it's the propulsion thread
			  if (i==4 && (apogee_flag || ejection_stage_flag >= DROGUE_DESCENT)){
				  osThreadTerminate(threadsID[i]);
			  }
			  else{
				 //Reset otherwise
				 NVIC_SystemReset();
			  }
		  }

		  /*
		  else if (thread_state == osThreadReady){ //For loop with a count to check if it's been too long?
		  }
		  else if (thread_state == osThreadRunning){
		  }
		  else if (thread_state == osThreadReserved){ TODO not sure what is this state
		  }
		  else if (thread_state == osThreadTerminated){not useful
		  }
		  */
	  }
	  #endif
}

/* USER CODE END Application */

/************************ (C) COPYRIGHT STMicroelectronics *****END OF FILE****/
